# LCM32F039 register map
File version: 1.0
CPU: CM0 r1p0, little endian, MPU, no FPU, 3 interrupt priority bits
Registers are 32-bit, read-write, reset 0x0 unless marked. A register's access mark holds for its fields unless they carry their own. Offsets are from the block's base; [hi:lo] are bit positions; {n}, {i} and the like mark numbered series.

## TIM1 — Advanced timer
Base 0x40010000
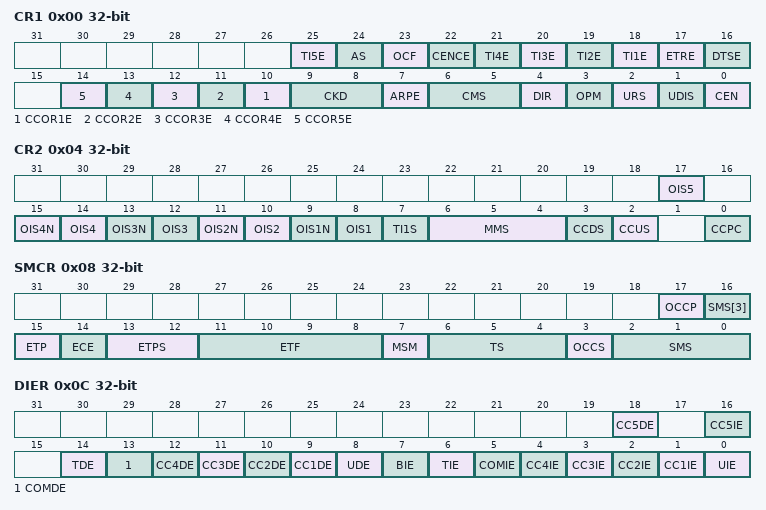
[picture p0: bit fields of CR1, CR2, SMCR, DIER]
0x00 CR1 — control register 1
  [25] TI5E — TI5 input detection/filter enable
  [24] AS — Active register selection for mcu read
  [23] OCF — OC/OCN asynchronous anti-glitch filter
  [22] CENCE — OCREF clear enable when CEN is disabled
  [n+17] TI{n}E (n=1..4) — TI{n} input detection/filter enable
  [17] ETRE — External trigger input detection/filter enable
  [16] DTSE — DTS clock enable
  [n+9] CCOR{n}E (n=1..5) — TI1 input detection/filter enable
  [9:8] CKD — Clock division
  [7] ARPE — Auto-reload preload enable
  [6:5] CMS — Center-aligned modeselection
  [4] DIR — Direction
  [3] OPM — One-pulse mode
  [2] URS — Update request source
  [1] UDIS — Update disable
  [0] CEN — Counter enable
0x04 CR2 — control register 2
  [17] OIS5 — Output Idle state 5
  [2n+7] OIS{n}N (n=1..4) — Output Idle state {n}
  [2n+6] OIS{n} (n=1..4) — Output Idle state {n}
  [7] TI1S — TI1 select
  [6:4] MMS — Master mode selection
  [3] CCDS — Capture/compare DMA selection
  [2] CCUS — Capture/compare control update selection
  [0] CCPC — Capture/compare preloaded control
0x08 SMCR — slave mode control register
  [17] OCCP — OCREF_CLR input polarity
  [16] SMS[3] — Slave mode selection - bit 3
  [15] ETP — External trigger polarity
  [14] ECE — External clock enable
  [13:12] ETPS — External trigger prescaler
  [11:8] ETF — External trigger filter
  [7] MSM — Master/Slave mode
  [6:4] TS — Trigger selection
  [3] OCCS — OCREF Clear Selection
  [2:0] SMS — Slave mode selection
0x0C DIER — DMA/Interrupt enable register
  [18] CC5DE — Capture/Compare 5 DMA request enable
  [16] CC5IE — Capture/Compare 5 interrupt enable
  [14] TDE — Trigger DMA request enable
  [13] COMDE — COM DMA request enable
  [n+8] CC{n}DE (n=1..4) — Capture/Compare {n} DMA request enable
  [8] UDE — Update DMA request enable
  [7] BIE — Break interrupt enable
  [6] TIE — Trigger interrupt enable
  [5] COMIE — COM interrupt enable
  [n] CC{n}IE (n=1..4) — Capture/Compare {n} interrupt enable
  [0] UIE — Update interrupt enable
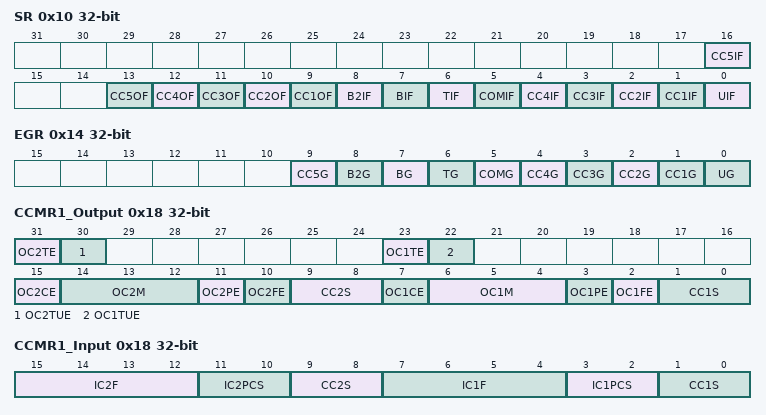
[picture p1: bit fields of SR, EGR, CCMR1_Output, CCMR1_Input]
0x10 SR — status register
  [16] CC5IF — Capture/Compare 5 interrupt flag
  [13] CC5OF — Capture/Compare 5 overcaptur flag
  [12] CC4OF — Capture/Compare 4 overcaptur flag
  [11] CC3OF — Capture/Compare 3 overcapture flag
  [10] CC2OF — Capture/compare 2 overcapture flag
  [9] CC1OF — Capture/Compare 1 overcapture flag
  [8] B2IF — Break 2 interrupt flag
  [7] BIF — Break interrupt flag
  [6] TIF — Trigger interrupt flag
  [5] COMIF — COM interrupt flag
  [4] CC4IF — Capture/Compare 4 interrupt flag
  [3] CC3IF — Capture/Compare 3 interrupt flag
  [2] CC2IF — Capture/Compare 2 interrupt flag
  [1] CC1IF — Capture/compare 1 interrupt flag
  [0] UIF — Update interrupt flag
0x14 EGR wo — event generation register
  [9] CC5G — Capture/compare 5 generation
  [8] B2G — Break2 generation
  [7] BG — Break generation
  [6] TG — Trigger generation
  [5] COMG — Capture/Compare control update generation
  [n] CC{n}G (n=1..4) — Capture/compare {n} generation
  [0] UG — Update generation
0x18 CCMR1_Output — capture/compare mode register (output mode)
  [31] OC2TE — OC2TE enable
  [30] OC2TUE — OC2TUE enable
  [23] OC1TE — OC1TE enable
  [22] OC1TUE — OC1TUE enable
  [15] OC2CE — OC2CE enable
  [14:12] OC2M — Output Compare 2 Mode
  [11] OC2PE — OC2PE enable
  [10] OC2FE — Output Compare 2 fast enable
  [9:8] CC2S — Capture/Compare 2 selection
  [7] OC1CE — Output Compare 1 clear enable
  [6:4] OC1M — Output Compare 1 mode
  [3] OC1PE — Output Compare 1 preload enable
  [2] OC1FE — Output Compare 1 fast enable
  [1:0] CC1S — Capture/Compare 1 selection
0x18 CCMR1_Input (alternate view of CCMR1_Output) — capture/compare mode register 1 (input mode)
  [15:12] IC2F — Input capture 2 filter
  [11:10] IC2PCS — Input capture 2 prescaler
  [9:8] CC2S — Capture/Compare 2 selection
  [7:4] IC1F — Input capture 1 filter
  [3:2] IC1PCS — Input capture 1 prescaler
  [1:0] CC1S — Capture/Compare 1 selection
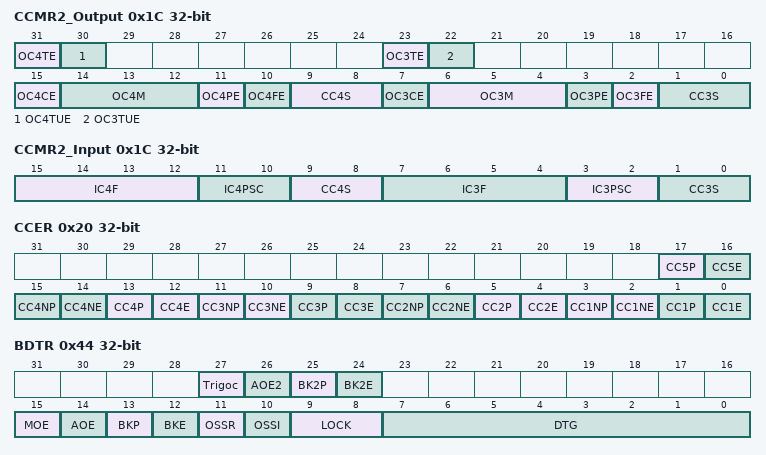
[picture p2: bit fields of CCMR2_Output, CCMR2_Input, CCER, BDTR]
0x1C CCMR2_Output — capture/compare mode register (output mode)
  [31] OC4TE — Output compare 4 trim enable
  [30] OC4TUE — Output compare 4 trim update enable
  [23] OC3TE — Output compare 3 trim enable
  [22] OC3TUE — Output compare 3 trim enable
  [15] OC4CE — Output compare 4 clear enable
  [14:12] OC4M — Output compare 4 mode
  [11] OC4PE — Output compare 4 preload enable
  [10] OC4FE — Output compare 4 fast enable
  [9:8] CC4S — Capture/Compare 4 selection
  [7] OC3CE — Output compare 3 clear enable
  [6:4] OC3M — Output compare 3 mode
  [3] OC3PE — Output compare 3 preload enable
  [2] OC3FE — Output compare 3 fast enable
  [1:0] CC3S — Capture/Compare 3 selection
0x1C CCMR2_Input (alternate view of CCMR2_Output) — capture/compare mode register 2 (input mode)
  [15:12] IC4F — Input capture 4 filter
  [11:10] IC4PSC — Input capture 4 prescaler
  [9:8] CC4S — Capture/Compare 4 selection
  [7:4] IC3F — Input capture 3 filter
  [3:2] IC3PSC — Input capture 3 prescaler
  [1:0] CC3S — Capture/compare 3 selection
0x20 CCER — capture/compare enable register
  [17] CC5P — Capture/Compare 5 output Polarity
  [4n-4] CC{n}E (n=1..5) — Capture/Compare {n} output enable
  [4n-1] CC{n}NP (n=1..4) — Capture/Compare {n} output Polarity
  [4n-2] CC{n}NE (n=1..4) — Capture/Compare {n} complementary output enable
  [13] CC4P — Capture/Compare 3 output Polarity
  [9] CC3P — Capture/Compare 3 output Polarity
  [5] CC2P — Capture/Compare 2 output Polarity
  [1] CC1P — Capture/Compare 1 output Polarity
0x24 CNT — counter
  [15:0] CNT — counter value
0x28 PSC — prescaler
  [15:0] PSC — Prescaler value
0x2C ARR — auto-reload register
  [15:0] ARR — Auto-reload value
0x30 RCR — Repeat count register
  [7:0] REP — Repeat counter value
0x34 CCR1 — capture/compare register 1
  [15:0] CCR1 — Capture/Compare 1 value
0x38 CCR2 — capture/compare register 2
  [15:0] CCR2 — Capture/Compare 2 value
0x3C CCR3 — capture/compare register 3
  [15:0] CCR3 — Capture/Compare value
0x40 CCR4 — capture/compare register 4
  [15:0] CCR4 — Capture/Compare value
0x44 BDTR — break and dead-time register
  [27] Trigoc — Trigger output is subject to brake enable position
  [26] AOE2 — Automatic output enable
  [25] BK2P — Break 2 polarity
  [24] BK2E — Break 2 enable
  [15] MOE — Main output enable
  [14] AOE — Automatic output enable
  [13] BKP — Break polarity
  [12] BKE — Break enable
  [11] OSSR — Off-state selection for Run mode
  [10] OSSI — Off-state selection for Idle mode
  [9:8] LOCK — Lock configuration
  [7:0] DTG — Dead-time generator setup
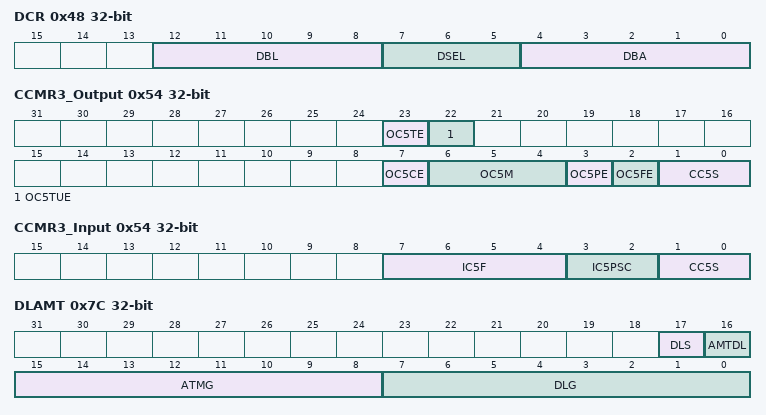
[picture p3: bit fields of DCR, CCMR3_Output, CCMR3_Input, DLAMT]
0x48 DCR — DMA control register
  [12:8] DBL — DMA burst length
  [7:5] DSEL — DSEL burst length
  [4:0] DBA — DMA base address
0x4C DMAR — DMA address for full transfer
  [15:0] DMAB — DMA register for burst accesses
0x54 CCMR3_Output — capture/compare mode register (output mode)
  [23] OC5TE — Output compare 5 trim enable
  [22] OC5TUE — Output compare 5 trim enable
  [7] OC5CE — Output compare 5 clear enable
  [6:4] OC5M — Output compare 4 mode
  [3] OC5PE — Output compare 4 preload enable
  [2] OC5FE — Output compare 4 fast enable
  [1:0] CC5S — Capture/Compare 4 selection
0x54 CCMR3_Input (alternate view of CCMR3_Output) — capture/compare mode register 3 (input mode)
  [7:4] IC5F — Input capture 4 filter
  [3:2] IC5PSC — Input capture 4 prescaler
  [1:0] CC5S — Capture/Compare 4 selection
0x58 CCR5 — capture/compare register 5
  [15:0] CCR5 — Capture/Compare value
{0x60+4i} CCTR{i} (i=1..5) — capture compare {i} repair register
  [15:0] CCTR{i} — capture compare {i} repair value
0x7C DLAMT — Delay and anti multiple trigger register
  [17] DLS — Is it allowed to clear ocxref during trigger delay
  [16] AMTDL — Start time selection of anti loss window
  [15:8] ATMG — Define AMT time
  [7:0] DLG — Define DLG time
{0x7C+4i} CCOR{i} (i=1..5) — Capture compare offset register {i}
  [15:0] CCOR{i} — Capture/compare {i} offset values

## TIM2 — General timer
Base 0x4001F000
Same registers: TIM3 0x4000B000
Registers as TIM1, without RCR, CCMR3_Output, CCMR3_Input, CCR5, CCTR{n} (n=1..5), DLAMT, CCOR{n} (n=1..5); these are added or differ:
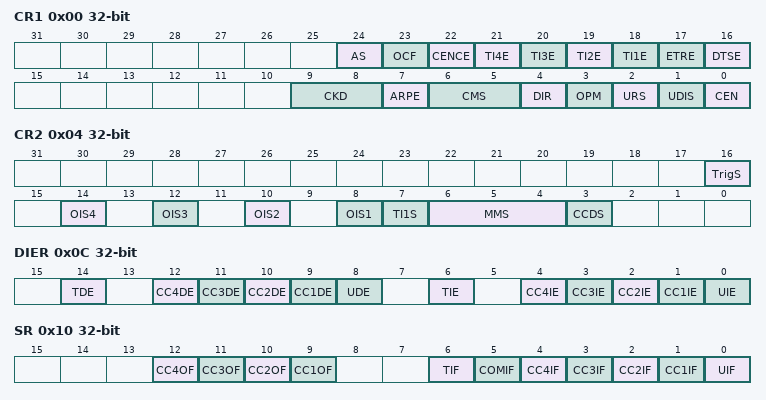
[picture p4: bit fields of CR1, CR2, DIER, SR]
0x00 CR1 — control register 1
  [24] AS — Active register selection for mcu read
  [23] OCF — OC/OCN asynchronous anti-glitch filter
  [22] CENCE — OCREF clear enable when CEN is disabled
  [n+17] TI{n}E (n=1..4) — TI{n} input detection/filter enable
  [17] ETRE — External trigger input detection/filter enable
  [16] DTSE — DTS clock enable
  [9:8] CKD — Clock division
  [7] ARPE — Auto-reload preload enable
  [6:5] CMS — Center-aligned modeselection
  [4] DIR — Direction
  [3] OPM — One-pulse mode
  [2] URS — Update request source
  [1] UDIS — Update disable
  [0] CEN — Counter enable
0x04 CR2 — control register 2
  [16] TrigS — Trigger select
  [2n+6] OIS{n} (n=1..4) — Output Idle state {n}
  [7] TI1S — TI1 select
  [6:4] MMS — Master mode selection
  [3] CCDS — Capture/compare DMA selection
0x0C DIER — DMA/Interrupt enable register
  [14] TDE — Trigger DMA request enable
  [n+8] CC{n}DE (n=1..4) — Capture/Compare {n} DMA request enable
  [8] UDE — Update DMA request enable
  [6] TIE — Trigger interrupt enable
  [n] CC{n}IE (n=1..4) — Capture/Compare {n} interrupt enable
  [0] UIE — Update interrupt enable
0x10 SR — status register
  [12] CC4OF — Capture/Compare 4 overcaptur flag
  [11] CC3OF — Capture/Compare 3 overcapture flag
  [10] CC2OF — Capture/compare 2 overcapture flag
  [9] CC1OF — Capture/Compare 1 overcapture flag
  [6] TIF — Trigger interrupt flag
  [5] COMIF — COM interrupt flag
  [4] CC4IF — Capture/Compare 4 interrupt flag
  [3] CC3IF — Capture/Compare 3 interrupt flag
  [2] CC2IF — Capture/Compare 2 interrupt flag
  [1] CC1IF — Capture/compare 1 interrupt flag
  [0] UIF — Update interrupt flag
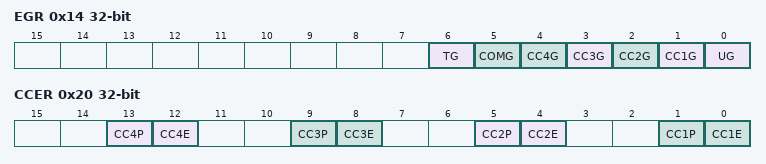
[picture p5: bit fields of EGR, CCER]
0x14 EGR wo — event generation register
  [6] TG — Trigger generation
  [5] COMG — Capture/Compare control update generation
  [n] CC{n}G (n=1..4) — Capture/compare {n} generation
  [0] UG — Update generation
0x20 CCER — capture/compare enable register
  [13] CC4P — Capture/Compare 3 output Polarity
  [4n-4] CC{n}E (n=1..4) — Capture/Compare {n} output enable
  [9] CC3P — Capture/Compare 3 output Polarity
  [5] CC2P — Capture/Compare 2 output Polarity
  [1] CC1P — Capture/Compare 1 output Polarity
